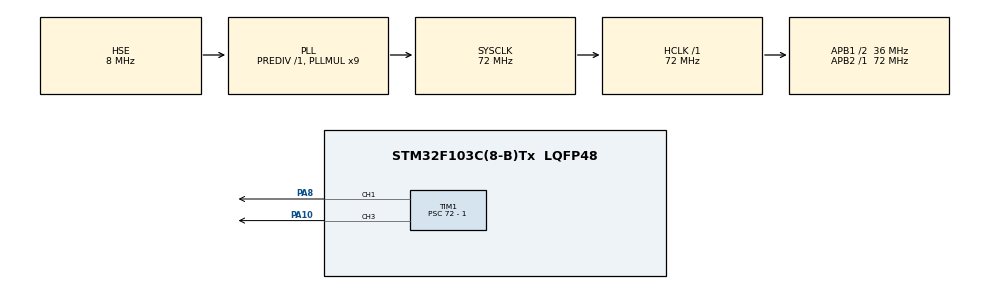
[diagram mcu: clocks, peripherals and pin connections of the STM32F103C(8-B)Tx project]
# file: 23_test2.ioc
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FREERTOS.Tasks01=defaultTask,24,128,StartDefaultTask,Default,NULL,Dynamic,NULL,NULL
Mcu.Family=STM32F1
Mcu.Name=STM32F103C(8-B)Tx
Mcu.Package=LQFP48
NVIC.PriorityGroup=NVIC_PRIORITYGROUP_4
NVIC.TIM2_IRQn=true\:5\:0\:false\:false\:true\:true\:true\:true\:true
NVIC.TIM4_IRQn=true\:15\:0\:false\:false\:true\:false\:false\:true\:true
NVIC.TimeBase=TIM4_IRQn
NVIC.TimeBaseIP=TIM4
PA10.Signal=S_TIM1_CH3
PA13.Mode=Serial_Wire
PA13.Signal=SYS_JTMS-SWDIO
PA14.Mode=Serial_Wire
PA14.Signal=SYS_JTCK-SWCLK
PA8.Signal=S_TIM1_CH1
PD0-OSC_IN.Mode=HSE-External-Oscillator
PD0-OSC_IN.Signal=RCC_OSC_IN
PD1-OSC_OUT.Mode=HSE-External-Oscillator
PD1-OSC_OUT.Signal=RCC_OSC_OUT
ProjectManager.HeapSize=0x200
ProjectManager.StackSize=0x400
ProjectManager.TargetToolchain=MDK-ARM V5.32
RCC.AHBFreq_Value=72000000
RCC.APB1CLKDivider=RCC_HCLK_DIV2
RCC.APB1Freq_Value=36000000
RCC.APB1TimFreq_Value=72000000
RCC.APB2Freq_Value=72000000
RCC.APB2TimFreq_Value=72000000
RCC.HCLKFreq_Value=72000000
RCC.PLLMUL=RCC_PLL_MUL9
RCC.PLLSourceVirtual=RCC_PLLSOURCE_HSE
RCC.SYSCLKFreq_VALUE=72000000
RCC.SYSCLKSource=RCC_SYSCLKSOURCE_PLLCLK
RCC.USBFreq_Value=72000000
SH.S_TIM1_CH1.0=TIM1_CH1,PWM Generation1 CH1
SH.S_TIM1_CH3.0=TIM1_CH3,PWM Generation3 CH3
TIM1.Channel-PWM\ Generation1\ CH1=TIM_CHANNEL_1
TIM1.Channel-PWM\ Generation3\ CH3=TIM_CHANNEL_3
TIM1.Period=1000-1
TIM1.Prescaler=72 - 1
TIM1.RepetitionCounter=0
TIM2.Period=1000-1
TIM2.Prescaler=72-1
VP_FREERTOS_VS_CMSIS_V2.Mode=CMSIS_V2
VP_SYS_VS_tim4.Mode=TIM4
VP_TIM1_VS_ClockSourceINT.Mode=Internal
VP_TIM2_VS_ClockSourceINT.Mode=Internal
board=custom

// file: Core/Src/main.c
/* USER CODE BEGIN Header */
/**
  ******************************************************************************
  * @file           : main.c
  * @brief          : Main program body
  ******************************************************************************
  * @attention
  *
  * Copyright (c) 2025 STMicroelectronics.
  * All rights reserved.
  *
  * This software is licensed under terms that can be found in the LICENSE file
  * in the root directory of this software component.
  * If no LICENSE file comes with this software, it is provided AS-IS.
  *
  ******************************************************************************
  */
/* USER CODE END Header */
#include "main.h"
#include "cmsis_os.h"
#include "tim.h"
#include "gpio.h"

/* USER CODE BEGIN PV */
int Tick = 0;
int flash = 0;
int pwmVal = 0;
int pwmIncrease = 1;
typedef enum{
	RED,
	YELLOW,
	GREEN,
	OFF,
}lightState;
lightState ledState = RED;
/* USER CODE END PV */

void SystemClock_Config(void);
void MX_FREERTOS_Init(void);

int main(void)
{

  /* MCU Configuration--------------------------------------------------------*/

  /* Reset of all peripherals, Initializes the Flash interface and the Systick. */
  HAL_Init();

  /* Configure the system clock */
  SystemClock_Config();

  /* Initialize all configured peripherals */
  MX_GPIO_Init();
  MX_TIM1_Init();
  MX_TIM2_Init();
  /* USER CODE BEGIN 2 */
	HAL_TIM_PWM_Start(&htim1,TIM_CHANNEL_1 | TIM_CHANNEL_3);
  /* USER CODE END 2 */

  /* Init scheduler */
  osKernelInitialize();  /* Call init function for freertos objects (in cmsis_os2.c) */
  MX_FREERTOS_Init();

  /* Start scheduler */
  osKernelStart();

  /* We should never get here as control is now taken by the scheduler */

  /* Infinite loop */
  while (1)
  {

  }
}

void SystemClock_Config(void)
{
  RCC_OscInitTypeDef RCC_OscInitStruct = {0};
  RCC_ClkInitTypeDef RCC_ClkInitStruct = {0};

  /** Initializes the RCC Oscillators according to the specified parameters
  * in the RCC_OscInitTypeDef structure.
  */
  RCC_OscInitStruct.OscillatorType = RCC_OSCILLATORTYPE_HSE;
  RCC_OscInitStruct.HSEState = RCC_HSE_ON;
  RCC_OscInitStruct.HSEPredivValue = RCC_HSE_PREDIV_DIV1;
  RCC_OscInitStruct.HSIState = RCC_HSI_ON;
  RCC_OscInitStruct.PLL.PLLState = RCC_PLL_ON;
  RCC_OscInitStruct.PLL.PLLSource = RCC_PLLSOURCE_HSE;
  RCC_OscInitStruct.PLL.PLLMUL = RCC_PLL_MUL9;
  if (HAL_RCC_OscConfig(&RCC_OscInitStruct) != HAL_OK)
  {
    Error_Handler();
  }

  /** Initializes the CPU, AHB and APB buses clocks
  */
  RCC_ClkInitStruct.ClockType = RCC_CLOCKTYPE_HCLK|RCC_CLOCKTYPE_SYSCLK
                              |RCC_CLOCKTYPE_PCLK1|RCC_CLOCKTYPE_PCLK2;
  RCC_ClkInitStruct.SYSCLKSource = RCC_SYSCLKSOURCE_PLLCLK;
  RCC_ClkInitStruct.AHBCLKDivider = RCC_SYSCLK_DIV1;
  RCC_ClkInitStruct.APB1CLKDivider = RCC_HCLK_DIV2;
  RCC_ClkInitStruct.APB2CLKDivider = RCC_HCLK_DIV1;

  if (HAL_RCC_ClockConfig(&RCC_ClkInitStruct, FLASH_LATENCY_2) != HAL_OK)
  {
    Error_Handler();
  }
}

void HAL_TIM_PeriodElapsedCallback(TIM_HandleTypeDef *htim)
{
  if (htim->Instance == TIM4)
  {
    HAL_IncTick();
  }
  /* USER CODE BEGIN Callback 1 */
	if(htim->Instance == TIM2){
		Tick++;
		if(pwmIncrease){
			pwmVal += 10;
			if(pwmVal >= 1000){
				pwmVal = 990;
				pwmIncrease = 0;
			}
		}else{
			pwmVal -= 10;
			if(pwmVal <= 0){
				pwmVal = 10;
				pwmIncrease = 1;
			}
		}
	}
	switch(ledState){
		case RED:
			__HAL_TIM_SET_COMPARE(&htim1,TIM_CHANNEL_3,pwmVal);
			__HAL_TIM_SET_COMPARE(&htim1,TIM_CHANNEL_1,0);
			if(Tick >= 5000){
				Tick = 0;
				ledState = YELLOW;
			}
			break;
		case YELLOW:
			__HAL_TIM_SET_COMPARE(&htim1,TIM_CHANNEL_1,pwmVal);
			__HAL_TIM_SET_COMPARE(&htim1,TIM_CHANNEL_3,pwmVal);
			if(Tick >= 1000){
				Tick = 0;
				flash++;
			}
			if(flash >= 3){
				flash = 0;
				ledState = GREEN;
			}
			break;
		case GREEN:
			__HAL_TIM_SET_COMPARE(&htim1,TIM_CHANNEL_3,0);
			__HAL_TIM_SET_COMPARE(&htim1,TIM_CHANNEL_1,pwmVal);
			if(Tick >= 5000){
				Tick = 0;
				ledState = OFF;
			}
			break;
		case OFF:
			__HAL_TIM_SET_COMPARE(&htim1,TIM_CHANNEL_3,0);
			__HAL_TIM_SET_COMPARE(&htim1,TIM_CHANNEL_1,0);
			break;
	}
  /* USER CODE END Callback 1 */
}

void Error_Handler(void)
{
  __disable_irq();
  while (1)
  {
  }
}

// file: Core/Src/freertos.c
/* USER CODE BEGIN Header */
/**
  ******************************************************************************
  * File Name          : freertos.c
  * Description        : Code for freertos applications
  ******************************************************************************
  * @attention
  *
  * Copyright (c) 2025 STMicroelectronics.
  * All rights reserved.
  *
  * This software is licensed under terms that can be found in the LICENSE file
  * in the root directory of this software component.
  * If no LICENSE file comes with this software, it is provided AS-IS.
  *
  ******************************************************************************
  */
/* USER CODE END Header */

#include "FreeRTOS.h"
#include "task.h"
#include "main.h"
#include "cmsis_os.h"

/* USER CODE BEGIN Includes */
#include <string.h>
#include "timers.h"
#include "tim.h"
/* USER CODE END Includes */

/* Definitions for defaultTask */
osThreadId_t defaultTaskHandle;
const osThreadAttr_t defaultTask_attributes = {
  .name = "defaultTask",
  .stack_size = 128 * 4,
  .priority = (osPriority_t) osPriorityNormal,
};

/* USER CODE BEGIN FunctionPrototypes */
void vMyTimerCallback(TimerHandle_t xTimer);
void vCreateAndStartTimer(void);
void vApplyTask(void *parames);
/* USER CODE END FunctionPrototypes */

void StartDefaultTask(void *argument);

void MX_FREERTOS_Init(void); /* (MISRA C 2004 rule 8.1) */

void MX_FREERTOS_Init(void) {

  /* Create the thread(s) */
  /* creation of defaultTask */
  defaultTaskHandle = osThreadNew(StartDefaultTask, NULL, &defaultTask_attributes);

}

void StartDefaultTask(void *argument)
{
  for(;;)
  {
    osDelay(1);
  }
}
